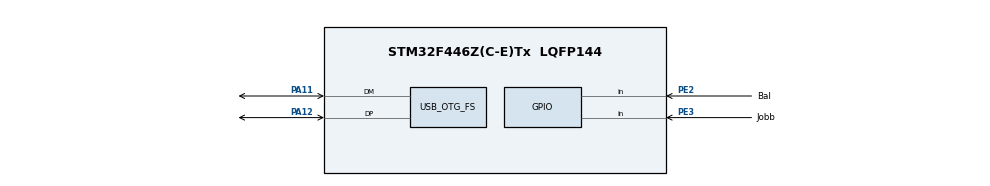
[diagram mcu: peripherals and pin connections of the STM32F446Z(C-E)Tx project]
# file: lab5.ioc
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Mcu.Family=STM32F4
Mcu.Name=STM32F446Z(C-E)Tx
Mcu.Package=LQFP144
NVIC.OTG_FS_IRQn=true\:0\:0\:false\:false\:true\:false\:true\:true
NVIC.PriorityGroup=NVIC_PRIORITYGROUP_4
PA11.Mode=Device_Only
PA11.Signal=USB_OTG_FS_DM
PA12.Mode=Device_Only
PA12.Signal=USB_OTG_FS_DP
PE2.GPIO_Label=Bal
PE2.GPIO_PuPd=GPIO_PULLDOWN
PE2.Signal=GPIO_Input
PE3.GPIO_Label=Jobb
PE3.GPIO_PuPd=GPIO_PULLDOWN
PE3.Signal=GPIO_Input
PH0-OSC_IN.Mode=HSE-External-Clock-Source
PH0-OSC_IN.Signal=RCC_OSC_IN
PH1-OSC_OUT.Mode=HSE-External-Clock-Source
PH1-OSC_OUT.Signal=RCC_OSC_OUT
ProjectManager.HeapSize=0x200
ProjectManager.StackSize=0x400
ProjectManager.TargetToolchain=STM32CubeIDE
RCC.CortexFreq_Value=16000000
RCC.HSE_VALUE=8000000
RCC.PLLM=4
RCC.PLLN=72
RCC.PLLQ=3
RCC.USBFreq_Value=48000000
RCC.VCOOutputFreq_Value=144000000
USB_DEVICE.CLASS_NAME_FS=HID
USB_DEVICE.VirtualMode-HID_FS=Hid
USB_DEVICE.VirtualModeFS=Hid_FS
USB_OTG_FS.VirtualMode=Device_Only
VP_USB_DEVICE_VS_USB_DEVICE_HID_FS.Mode=HID_FS
board=custom

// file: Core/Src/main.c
/* USER CODE BEGIN Header */
/**
  ******************************************************************************
  * @file           : main.c
  * @brief          : Main program body
  ******************************************************************************
  * @attention
  *
  * Copyright (c) 2026 STMicroelectronics.
  * All rights reserved.
  *
  * This software is licensed under terms that can be found in the LICENSE file
  * in the root directory of this software component.
  * If no LICENSE file comes with this software, it is provided AS-IS.
  *
  ******************************************************************************
  */
/* USER CODE END Header */
#include "main.h"
#include "usb_device.h"

/* USER CODE BEGIN Includes */
#include "usbd_hid.h"
/* USER CODE END Includes */

void SystemClock_Config(void);
static void MX_GPIO_Init(void);

/* USER CODE BEGIN 0 */
struct mouse_report_t {
    uint8_t buttons;
    int8_t x;
    int8_t y;
    int8_t wheel;
};
struct mouse_report_t mouseHID;

extern USBD_HandleTypeDef hUsbDeviceFS;
/* USER CODE END 0 */

int main(void)
{

  /* MCU Configuration--------------------------------------------------------*/

  /* Reset of all peripherals, Initializes the Flash interface and the Systick. */
  HAL_Init();

  /* Configure the system clock */
  SystemClock_Config();

  /* Initialize all configured peripherals */
  MX_GPIO_Init();
  MX_USB_DEVICE_Init();
  /* USER CODE BEGIN 2 */
  mouseHID.buttons = 0;
  mouseHID.x = 0;
  mouseHID.y = 0;
  mouseHID.wheel = 0;
  /* USER CODE END 2 */

  /* Infinite loop */
  while (1)
  {

	  /* USER CODE BEGIN 3 */
	  mouseHID.buttons = 0;
	  mouseHID.x = 0;
	  mouseHID.y = 0;

	  if (HAL_GPIO_ReadPin(Bal_GPIO_Port, Bal_Pin))
	  {
		mouseHID.buttons |= 1;
	  }
	  if (HAL_GPIO_ReadPin(Jobb_GPIO_Port, Jobb_Pin))
	  {
		mouseHID.buttons |= 2;
	  }

	  USBD_HID_SendReport(&hUsbDeviceFS, (uint8_t *)&mouseHID, sizeof(struct mouse_report_t));

	  HAL_Delay(50);
  }
}

void SystemClock_Config(void)
{
  RCC_OscInitTypeDef RCC_OscInitStruct = {0};
  RCC_ClkInitTypeDef RCC_ClkInitStruct = {0};

  /** Configure the main internal regulator output voltage
  */
  __HAL_RCC_PWR_CLK_ENABLE();
  __HAL_PWR_VOLTAGESCALING_CONFIG(PWR_REGULATOR_VOLTAGE_SCALE3);

  /** Initializes the RCC Oscillators according to the specified parameters
  * in the RCC_OscInitTypeDef structure.
  */
  RCC_OscInitStruct.OscillatorType = RCC_OSCILLATORTYPE_HSI;
  RCC_OscInitStruct.HSIState = RCC_HSI_ON;
  RCC_OscInitStruct.HSICalibrationValue = RCC_HSICALIBRATION_DEFAULT;
  RCC_OscInitStruct.PLL.PLLState = RCC_PLL_ON;
  RCC_OscInitStruct.PLL.PLLSource = RCC_PLLSOURCE_HSE;
  RCC_OscInitStruct.PLL.PLLM = 4;
  RCC_OscInitStruct.PLL.PLLN = 72;
  RCC_OscInitStruct.PLL.PLLP = RCC_PLLP_DIV2;
  RCC_OscInitStruct.PLL.PLLQ = 3;
  RCC_OscInitStruct.PLL.PLLR = 2;
  if (HAL_RCC_OscConfig(&RCC_OscInitStruct) != HAL_OK)
  {
    Error_Handler();
  }

  /** Initializes the CPU, AHB and APB buses clocks
  */
  RCC_ClkInitStruct.ClockType = RCC_CLOCKTYPE_HCLK|RCC_CLOCKTYPE_SYSCLK
                              |RCC_CLOCKTYPE_PCLK1|RCC_CLOCKTYPE_PCLK2;
  RCC_ClkInitStruct.SYSCLKSource = RCC_SYSCLKSOURCE_HSI;
  RCC_ClkInitStruct.AHBCLKDivider = RCC_SYSCLK_DIV1;
  RCC_ClkInitStruct.APB1CLKDivider = RCC_HCLK_DIV1;
  RCC_ClkInitStruct.APB2CLKDivider = RCC_HCLK_DIV1;

  if (HAL_RCC_ClockConfig(&RCC_ClkInitStruct, FLASH_LATENCY_0) != HAL_OK)
  {
    Error_Handler();
  }
}

static void MX_GPIO_Init(void)
{
  GPIO_InitTypeDef GPIO_InitStruct = {0};

  /* GPIO Ports Clock Enable */
  __HAL_RCC_GPIOE_CLK_ENABLE();
  __HAL_RCC_GPIOH_CLK_ENABLE();
  __HAL_RCC_GPIOA_CLK_ENABLE();

  /*Configure GPIO pins : Bal_Pin Jobb_Pin */
  GPIO_InitStruct.Pin = Bal_Pin|Jobb_Pin;
  GPIO_InitStruct.Mode = GPIO_MODE_INPUT;
  GPIO_InitStruct.Pull = GPIO_PULLDOWN;
  HAL_GPIO_Init(GPIOE, &GPIO_InitStruct);

}

void Error_Handler(void)
{
  __disable_irq();
  while (1)
  {
  }
}
